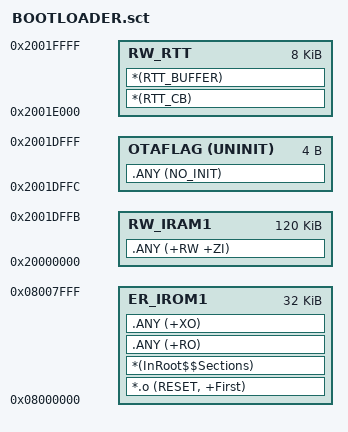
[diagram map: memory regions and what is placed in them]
; *************************************************************
; *** Scatter-Loading Description File for BOOTLOADER target **
; *************************************************************

LR_IROM1 0x08000000 0x00008000  {    ; load region size_region
  ER_IROM1 0x08000000 0x00008000  {  ; load address = execution address
   *.o (RESET, +First)
   *(InRoot$$Sections)
   .ANY (+RO)
   .ANY (+XO)
  }

  RW_IRAM1 0x20000000 0x0001DFFC  {  ; RW data
   .ANY (+RW +ZI)
  }
  OTAFLAG  0x2001DFFC UNINIT 0x00000004  {  ; reset-persistent jump flag
   .ANY (NO_INIT)
  }
  RW_RTT   0x2001E000 0x00002000  {  ; RTT fixed RAM region (CB + buffers)
   *(RTT_CB)
   *(RTT_BUFFER)
  }

}
